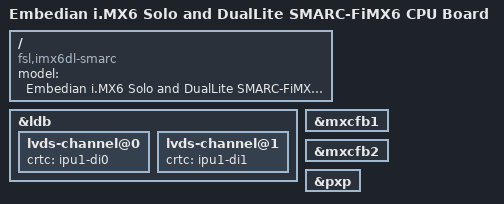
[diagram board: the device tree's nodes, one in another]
// SPDX-License-Identifier: GPL-2.0
//
// Copyright (C) 2013 Freescale Semiconductor, Inc.
// Copyright (C) 2024 Embedian, Inc.

/dts-v1/;

#include "imx6dl.dtsi"
#include "imx6qdl-smarc.dtsi"

/ {
	model = "Embedian i.MX6 Solo and DualLite SMARC-FiMX6 CPU Board";
	compatible = "fsl,imx6dl-smarc", "fsl,imx6dl";
};

&ldb {
	lvds-channel@0 {
		crtc = "ipu1-di0";
	};

	lvds-channel@1 {
		crtc = "ipu1-di1";
	};
};

&mxcfb1 {
	status = "okay";
};

&mxcfb2 {
	status = "okay";
};

&pxp {
	status = "okay";
};
